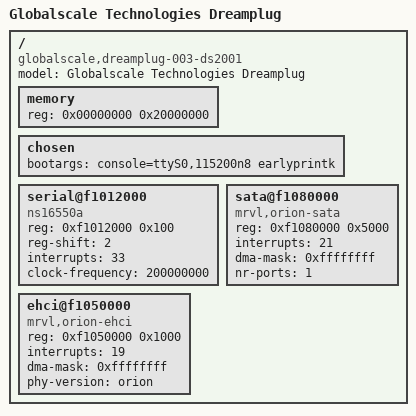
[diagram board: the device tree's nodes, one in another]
/dts-v1/;

/include/ "kirkwood.dtsi"

/ {
	model = "Globalscale Technologies Dreamplug";
	compatible = "globalscale,dreamplug-003-ds2001", "globalscale,dreamplug", "mrvl,kirkwood-88f6281", "mrvl,kirkwood";

	memory {
		device_type = "memory";
		reg = <0x00000000 0x20000000>;
	};

	chosen {
		bootargs = "console=ttyS0,115200n8 earlyprintk";
	};

	serial@f1012000 {
		compatible = "ns16550a";
		reg = <0xf1012000 0x100>;
		reg-shift = <2>;
		interrupts = <33>;
		clock-frequency = <200000000>;
	};

	sata@f1080000 {
		compatible = "mrvl,orion-sata";
		reg = <0xf1080000 0x5000>;
		interrupts = <21>;
		dma-mask = <0xffffffff>;
		nr-ports = <1>;
	};

	ehci@f1050000 {
		compatible = "mrvl,orion-ehci";
		reg = <0xf1050000 0x1000>;
		interrupts = <19>;
		dma-mask = <0xffffffff>;
		phy-version = "orion";
	};
};
